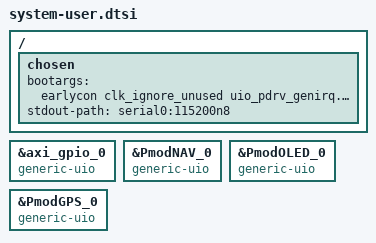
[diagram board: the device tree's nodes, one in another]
/include/ "system-conf.dtsi"

/ {
    chosen {
        bootargs = "earlycon clk_ignore_unused uio_pdrv_genirq.of_id=generic-uio";
        stdout-path = "serial0:115200n8";
    };
};

&axi_gpio_0{
    compatible = "generic-uio";
};

&PmodNAV_0{
    compatible = "generic-uio";
};

&PmodOLED_0{
    compatible = "generic-uio";
};

&PmodGPS_0 {
    compatible = "generic-uio";
    status = "okay";
};
